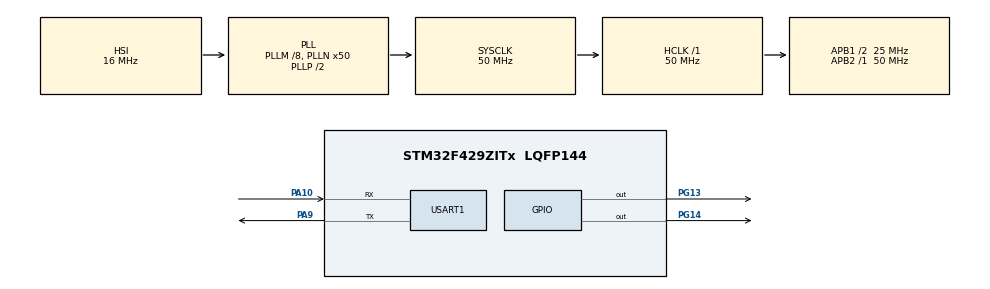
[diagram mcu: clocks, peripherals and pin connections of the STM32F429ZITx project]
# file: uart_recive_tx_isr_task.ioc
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FREERTOS.Queues01=myQueue01,16,uint16_t,0,Dynamic,NULL,NULL
FREERTOS.Tasks01=Blink_led,24,128,Start_blink_led,Default,NULL,Dynamic,NULL,NULL
FREERTOS.configUSE_NEWLIB_REENTRANT=1
Mcu.Family=STM32F4
Mcu.Name=STM32F429ZITx
Mcu.Package=LQFP144
NVIC.PriorityGroup=NVIC_PRIORITYGROUP_4
NVIC.TIM1_UP_TIM10_IRQn=true\:15\:0\:false\:false\:true\:false\:false\:true\:true
NVIC.TimeBase=TIM1_UP_TIM10_IRQn
NVIC.TimeBaseIP=TIM1
NVIC.USART1_IRQn=true\:5\:0\:false\:false\:true\:true\:true\:true\:true
PA10.Mode=Asynchronous
PA10.Signal=USART1_RX
PA9.Mode=Asynchronous
PA9.Signal=USART1_TX
PG13.Signal=GPIO_Output
PG14.Signal=GPIO_Output
PH0/OSC_IN.Mode=HSE-External-Oscillator
PH0/OSC_IN.Signal=RCC_OSC_IN
PH1/OSC_OUT.Mode=HSE-External-Oscillator
PH1/OSC_OUT.Signal=RCC_OSC_OUT
ProjectManager.HeapSize=0x200
ProjectManager.StackSize=0x400
ProjectManager.TargetToolchain=STM32CubeIDE
RCC.48MHZClocksFreq_Value=25000000
RCC.AHBFreq_Value=50000000
RCC.APB1CLKDivider=RCC_HCLK_DIV2
RCC.APB1Freq_Value=25000000
RCC.APB1TimFreq_Value=50000000
RCC.APB2Freq_Value=50000000
RCC.APB2TimFreq_Value=50000000
RCC.CortexFreq_Value=50000000
RCC.HCLKFreq_Value=50000000
RCC.HSE_VALUE=25000000
RCC.HSI_VALUE=16000000
RCC.LSE_VALUE=32768
RCC.PLLM=8
RCC.PLLN=50
RCC.SYSCLKFreq_VALUE=50000000
RCC.SYSCLKSource=RCC_SYSCLKSOURCE_PLLCLK
RCC.VCOOutputFreq_Value=100000000
USART1.VirtualMode=VM_ASYNC
VP_FREERTOS_VS_CMSIS_V2.Mode=CMSIS_V2
VP_SYS_VS_tim1.Mode=TIM1
board=custom

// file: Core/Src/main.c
/* USER CODE BEGIN Header */
/**
  ******************************************************************************
  * @file           : main.c
  * @brief          : Main program body
  ******************************************************************************
  * @attention
  *
  * Copyright (c) 2025 STMicroelectronics.
  * All rights reserved.
  *
  * This software is licensed under terms that can be found in the LICENSE file
  * in the root directory of this software component.
  * If no LICENSE file comes with this software, it is provided AS-IS.
  *
  ******************************************************************************
  */
/* USER CODE END Header */
#include "main.h"
#include "cmsis_os.h"
//#include "log.h"

UART_HandleTypeDef huart1;

/* Definitions for Blink_led */
osThreadId_t Blink_ledHandle;
const osThreadAttr_t Blink_led_attributes = {
  .name = "Blink_led",
  .stack_size = 128 * 4,
  .priority = (osPriority_t) osPriorityNormal,
};
/* Definitions for myQueue01 */
osMessageQueueId_t myQueue01Handle;
const osMessageQueueAttr_t myQueue01_attributes = {
  .name = "myQueue01"
};
/* USER CODE BEGIN PV */
uint8_t rxData;
/* USER CODE END PV */

void SystemClock_Config(void);
static void MX_GPIO_Init(void);
static void MX_USART1_UART_Init(void);
void Start_blink_led(void *argument);
void HAL_UART_RxCpltCallback(UART_HandleTypeDef *huart);

/* USER CODE BEGIN PFP */
uint8_t ch='c';
/* USER CODE END PFP */

/* USER CODE BEGIN 0 */
void HAL_UART_RxCpltCallback(UART_HandleTypeDef *huart)
{
    if (huart->Instance == USART1) {
    	//LOG_INFO("UART RX Callback: Received data: %c", rxData);
        osMessageQueuePut(myQueue01Handle, &rxData, 0, 0);
        HAL_UART_Receive_IT(&huart1, &rxData, 1);
    }
}
/* USER CODE END 0 */

int main(void)
{

  /* MCU Configuration--------------------------------------------------------*/

  /* Reset of all peripherals, Initializes the Flash interface and the Systick. */
  HAL_Init();

  /* Configure the system clock */
  SystemClock_Config();

  /* Initialize all configured peripherals */
  MX_GPIO_Init();
  MX_USART1_UART_Init();

  /* Init scheduler */
  osKernelInitialize();

  /* Create the queue(s) */
  /* creation of myQueue01 */
  myQueue01Handle = osMessageQueueNew (16, sizeof(uint16_t), &myQueue01_attributes);

  HAL_UART_Receive_IT(&huart1, &rxData, 1);
  HAL_UART_Transmit(&huart1,&ch, 1,HAL_MAX_DELAY);

  /* Create the thread(s) */
  /* creation of Blink_led */
  Blink_ledHandle = osThreadNew(Start_blink_led, NULL, &Blink_led_attributes);

  /* Start scheduler */
  osKernelStart();

  /* We should never get here as control is now taken by the scheduler */

  /* Infinite loop */
  while (1)
  {

  }
}

void SystemClock_Config(void)
{
  RCC_OscInitTypeDef RCC_OscInitStruct = {0};
  RCC_ClkInitTypeDef RCC_ClkInitStruct = {0};

  /** Configure the main internal regulator output voltage
  */
  __HAL_RCC_PWR_CLK_ENABLE();
  __HAL_PWR_VOLTAGESCALING_CONFIG(PWR_REGULATOR_VOLTAGE_SCALE3);

  /** Initializes the RCC Oscillators according to the specified parameters
  * in the RCC_OscInitTypeDef structure.
  */
  RCC_OscInitStruct.OscillatorType = RCC_OSCILLATORTYPE_HSI;
  RCC_OscInitStruct.HSIState = RCC_HSI_ON;
  RCC_OscInitStruct.HSICalibrationValue = RCC_HSICALIBRATION_DEFAULT;
  RCC_OscInitStruct.PLL.PLLState = RCC_PLL_ON;
  RCC_OscInitStruct.PLL.PLLSource = RCC_PLLSOURCE_HSI;
  RCC_OscInitStruct.PLL.PLLM = 8;
  RCC_OscInitStruct.PLL.PLLN = 50;
  RCC_OscInitStruct.PLL.PLLP = RCC_PLLP_DIV2;
  RCC_OscInitStruct.PLL.PLLQ = 4;
  if (HAL_RCC_OscConfig(&RCC_OscInitStruct) != HAL_OK)
  {
    Error_Handler();
  }

  /** Initializes the CPU, AHB and APB buses clocks
  */
  RCC_ClkInitStruct.ClockType = RCC_CLOCKTYPE_HCLK|RCC_CLOCKTYPE_SYSCLK
                              |RCC_CLOCKTYPE_PCLK1|RCC_CLOCKTYPE_PCLK2;
  RCC_ClkInitStruct.SYSCLKSource = RCC_SYSCLKSOURCE_PLLCLK;
  RCC_ClkInitStruct.AHBCLKDivider = RCC_SYSCLK_DIV1;
  RCC_ClkInitStruct.APB1CLKDivider = RCC_HCLK_DIV2;
  RCC_ClkInitStruct.APB2CLKDivider = RCC_HCLK_DIV1;

  if (HAL_RCC_ClockConfig(&RCC_ClkInitStruct, FLASH_LATENCY_1) != HAL_OK)
  {
    Error_Handler();
  }
}

static void MX_USART1_UART_Init(void)
{

  huart1.Instance = USART1;
  huart1.Init.BaudRate = 115200;
  huart1.Init.WordLength = UART_WORDLENGTH_8B;
  huart1.Init.StopBits = UART_STOPBITS_1;
  huart1.Init.Parity = UART_PARITY_NONE;
  huart1.Init.Mode = UART_MODE_TX_RX;
  huart1.Init.HwFlowCtl = UART_HWCONTROL_NONE;
  huart1.Init.OverSampling = UART_OVERSAMPLING_16;
  if (HAL_UART_Init(&huart1) != HAL_OK)
  {
    Error_Handler();
  }

}

static void MX_GPIO_Init(void)
{
  GPIO_InitTypeDef GPIO_InitStruct = {0};

  /* GPIO Ports Clock Enable */
  __HAL_RCC_GPIOH_CLK_ENABLE();
  __HAL_RCC_GPIOA_CLK_ENABLE();
  __HAL_RCC_GPIOG_CLK_ENABLE();

  /*Configure GPIO pin Output Level */
  HAL_GPIO_WritePin(GPIOG, GPIO_PIN_13|GPIO_PIN_14, GPIO_PIN_RESET);

  /*Configure GPIO pins : PG13 PG14 */
  GPIO_InitStruct.Pin = GPIO_PIN_13|GPIO_PIN_14;
  GPIO_InitStruct.Mode = GPIO_MODE_OUTPUT_PP;
  GPIO_InitStruct.Pull = GPIO_NOPULL;
  GPIO_InitStruct.Speed = GPIO_SPEED_FREQ_LOW;
  HAL_GPIO_Init(GPIOG, &GPIO_InitStruct);

}

void Start_blink_led(void *argument)
{
  /* USER CODE BEGIN 5 */
	uint8_t recived;
  /* Infinite loop */
  for(;;)
  {
    if(osMessageQueueGet(myQueue01Handle,&recived,NULL,osWaitForever)==osOK)
    {
    	//LOG_DEBUG("Message received: %c", recived);
    	if(recived=='a')
    	{
    		HAL_GPIO_TogglePin(GPIOG,GPIO_PIN_13);
    		//LOG_INFO("LED 1 toggled");
    		HAL_UART_Transmit(&huart1,&ch, 1,HAL_MAX_DELAY);

    	}
    	else
    	{
    		HAL_GPIO_TogglePin(GPIOG,GPIO_PIN_14);
    		//LOG_INFO("LED 2 toggled");
    		//HAL_UART_Transmit(&huart1,&ch, 1,HAL_MAX_DELAY);

    	}
    }
  }
  /* USER CODE END 5 */
}

void HAL_TIM_PeriodElapsedCallback(TIM_HandleTypeDef *htim)
{
  if (htim->Instance == TIM1) {
    HAL_IncTick();
  }
}

void Error_Handler(void)
{
  __disable_irq();
  while (1)
  {
  }
}
